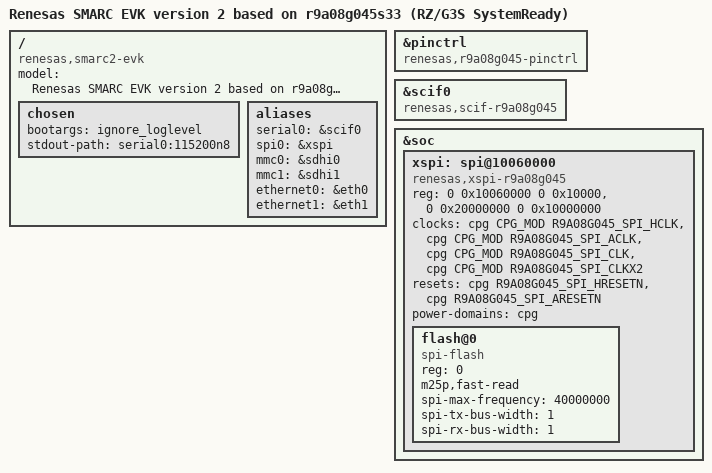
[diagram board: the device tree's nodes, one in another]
// SPDX-License-Identifier: (GPL-2.0-only OR BSD-2-Clause)
/*
 * Device Tree Source for the RZ/G3S SMARC EVK board.
 * Based on the Linux kernel r9a08g045s33-smarc device tree for ARM
 * SystemReady compliance, so U-Boot boots from and hands the kernel the
 * same device tree.
 *
 * Copyright (C) 2024 Renesas Electronics Corp.
 */

/dts-v1/;

#include <dt-bindings/gpio/gpio.h>
#include <dt-bindings/pinctrl/rzg2l-pinctrl.h>
#include "r9a08g045.dtsi"
#include "r9a08g045s-u-boot.dtsi"
#include "rzg3s-smarc-som.dtsi"
#include "rzg3s-smarc.dtsi"

/ {
	model = "Renesas SMARC EVK version 2 based on r9a08g045s33 (RZ/G3S SystemReady)";
	compatible = "renesas,smarc2-evk", "renesas,rzg3s-smarcm",
		     "renesas,r9a08g045s33", "renesas,r9a08g045";

	/* Override chosen for U-Boot */
	chosen {
		bootargs = "ignore_loglevel";
		stdout-path = "serial0:115200n8";
	};

	/* Override aliases for proper device ordering */
	aliases {
		serial0 = &scif0;
		spi0 = &xspi;
		mmc0 = &sdhi0;
		mmc1 = &sdhi1;
		ethernet0 = &eth0;
		ethernet1 = &eth1;
	};
};


&pinctrl {
	compatible = "renesas,r9a08g045-pinctrl", "renesas,r9a08g045s-pinctrl";
};


&scif0 {
	compatible = "renesas,scif-r9a08g045", "renesas,scif-r9a07g044",
		     "renesas,scif";
};

&soc {
	xspi: spi@10060000 {
		compatible = "renesas,xspi-r9a08g045";
		reg = <0 0x10060000 0 0x10000>,
		      <0 0x20000000 0 0x10000000>;
		clocks = <&cpg CPG_MOD R9A08G045_SPI_HCLK>,
			 <&cpg CPG_MOD R9A08G045_SPI_ACLK>,
			 <&cpg CPG_MOD R9A08G045_SPI_CLK>,
			 <&cpg CPG_MOD R9A08G045_SPI_CLKX2>;
		resets = <&cpg R9A08G045_SPI_HRESETN>,
			 <&cpg R9A08G045_SPI_ARESETN>;
		power-domains = <&cpg>;
		#address-cells = <1>;
		#size-cells = <0>;

		flash@0 {
			compatible = "spi-flash", "jedec,spi-nor";
			reg = <0>;
			m25p,fast-read;
			spi-max-frequency = <40000000>;
			spi-tx-bus-width = <1>;
			spi-rx-bus-width = <1>;
		};
	};
};
